# CONTROLSS_MDLXBAR_CONTROLSS_MDLXBAR register map
Vendor: Texas Instruments
Peripheral module from a debugger description file (folder AM263).
Registers are 32-bit, read-write, reset 0x0 unless marked. A register's access mark holds for its fields unless they carry their own. Offsets are as the file gives them; lines under a group give offsets from that group; [hi:lo] are bit positions; {n}, {i} and the like mark numbered series; 'fields as' and 'values as' point back to an identical list; <NAME> marks a mode.

## CONTROLSS_MDLXBAR_CONTROLSS_MDLXBAR
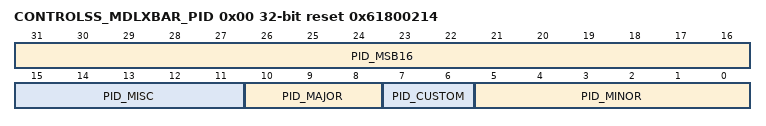
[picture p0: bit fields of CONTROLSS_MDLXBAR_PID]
0x00 CONTROLSS_MDLXBAR_PID ro reset 0x61800214
  [31:16] PID_MSB16 — Not Defined
  [15:11] PID_MISC — Not Defined
  [10:8] PID_MAJOR — Not Defined
  [7:6] PID_CUSTOM — Not Defined
  [5:0] PID_MINOR — Not Defined
{0x100+0x40*i} CONTROLSS_MDLXBAR_MDLXBAR{i}_G0 (i=0..15)
  [31:0] SEL — MDL XBar{i} G0 input bit select. Input source is PWMA sclk select1: PWMA sclk bit[x] selected0: PWMA sclk bit[x] is de-selected
{0x104+0x40*i} CONTROLSS_MDLXBAR_MDLXBAR{i}_G1 (i=0..15)
  [31:0] SEL — MDL XBar{i} G1 input bit select. Input source is PWMB sclk select1: PWMB sclk bit[x] selected0: PWMB sclk bit[x] is de-selected
{0x108+0x40*i} CONTROLSS_MDLXBAR_MDLXBAR{i}_G2 (i=0..15)
  [31:0] SEL — MDL XBar{i} G2 input bit select. Input source is ICSS GPO selecty=0 when x =0 to 15, y=1 when x=16 to 311: ICSS_PORT[y].GPO[x] selected.0: ICSS_PORT[y].GPO[x] is de-selected
